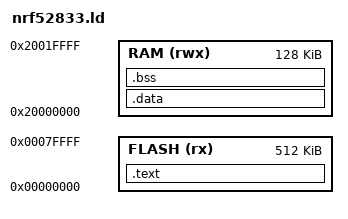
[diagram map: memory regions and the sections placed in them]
MEMORY
{
    FLASH (rx) : ORIGIN = 0X00000000, LENGTH = 512K
    RAM   (rwx): ORIGIN = 0X20000000, LENGTH = 128K
}

ENTRY(Reset_Handler)

SECTIONS
{
    .text :
    {
        KEEP(*(.isr_vector))
        *(.text*)
        *(.rodata*)
        . = ALIGN(4);
        _etext = .;
    }   > FLASH

    _sidata = LOADADDR(.data);

    .data : AT (_etext)
    {
        _sdata = .;
        *(.data*)
        . = ALIGN(4);
        _edata = .;
    } > RAM

    .bss :
    {
        _sbss = .;
        *(.bss*)
        *(COMMON)
        . = ALIGN(4);
        _ebss = .;
    } > RAM

    _estack = ORIGIN(RAM) + LENGTH(RAM);
}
